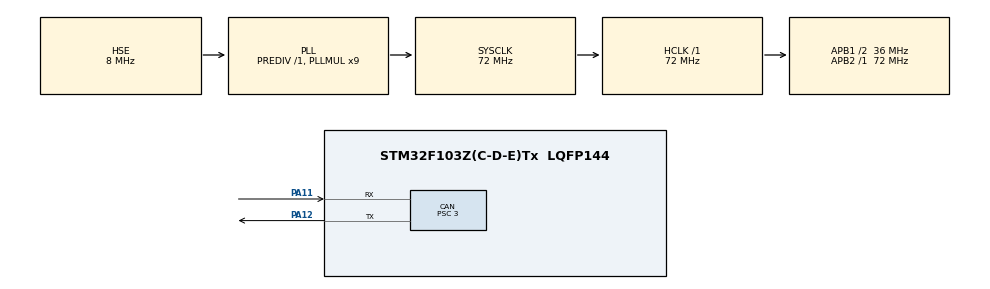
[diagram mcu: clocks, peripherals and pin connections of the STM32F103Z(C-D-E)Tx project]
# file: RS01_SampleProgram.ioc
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CAN.BS1=CAN_BS1_6TQ
CAN.BS2=CAN_BS2_5TQ
CAN.CalculateBaudRate=1000000
CAN.CalculateTimeBit=999.99
CAN.CalculateTimeQuantum=83.33333333333334
CAN.Prescaler=3
Mcu.Family=STM32F1
Mcu.Name=STM32F103Z(C-D-E)Tx
Mcu.Package=LQFP144
NVIC.PriorityGroup=NVIC_PRIORITYGROUP_4
NVIC.USB_LP_CAN1_RX0_IRQn=true\:0\:0\:false\:false\:true\:true\:true
OSC_IN.Mode=HSE-External-Oscillator
OSC_IN.Signal=RCC_OSC_IN
OSC_OUT.Mode=HSE-External-Oscillator
OSC_OUT.Signal=RCC_OSC_OUT
PA11.Mode=CAN_Activate
PA11.Signal=CAN_RX
PA12.Mode=CAN_Activate
PA12.Signal=CAN_TX
PA13.Mode=Serial_Wire
PA13.Signal=SYS_JTMS-SWDIO
PA14.Mode=Serial_Wire
PA14.Signal=SYS_JTCK-SWCLK
ProjectManager.HeapSize=0x200
ProjectManager.StackSize=0x400
ProjectManager.TargetToolchain=MDK-ARM V5.32
RCC.AHBFreq_Value=72000000
RCC.APB1CLKDivider=RCC_HCLK_DIV2
RCC.APB1Freq_Value=36000000
RCC.APB1TimFreq_Value=72000000
RCC.APB2Freq_Value=72000000
RCC.APB2TimFreq_Value=72000000
RCC.HCLKFreq_Value=72000000
RCC.PLLMUL=RCC_PLL_MUL9
RCC.PLLSourceVirtual=RCC_PLLSOURCE_HSE
RCC.SYSCLKFreq_VALUE=72000000
RCC.SYSCLKSource=RCC_SYSCLKSOURCE_PLLCLK
RCC.USBFreq_Value=72000000
board=custom

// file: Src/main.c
/* USER CODE BEGIN Header */
/**
  ******************************************************************************
  * @file           : main.c
  * @brief          : Main program body
  ******************************************************************************
  * @attention
  *
  * <h2><center>&copy; Copyright (c) 2025 STMicroelectronics.
  * All rights reserved.</center></h2>
  *
  * This software component is licensed by ST under BSD 3-Clause license,
  * the "License"; You may not use this file except in compliance with the
  * License. You may obtain a copy of the License at:
  *                        opensource.org/licenses/BSD-3-Clause
  *
  ******************************************************************************
  */
/* USER CODE END Header */
#include "main.h"
#include "can.h"
#include "gpio.h"

/* USER CODE BEGIN Includes */

#include "RobStride.h"
/* USER CODE END Includes */

void SystemClock_Config(void);
/* USER CODE BEGIN PFP */
CAN_FilterTypeDef CAN_FilterStrue;
CAN_TxHeaderTypeDef CAN_TxHeaderStrue;
CAN_RxHeaderTypeDef CAN_RxHeaderStrue;
uint8_t pRxdata[8], pTxdata[8];
RobStride_Motor RobStride_01(0x7F, false);

uint8_t mode = 0;
/* USER CODE END PFP */

int main(void)
{

  /* MCU Configuration--------------------------------------------------------*/

  /* Reset of all peripherals, Initializes the Flash interface and the Systick. */
  HAL_Init();

  /* Configure the system clock */
  SystemClock_Config();

  /* Initialize all configured peripherals */
  MX_GPIO_Init();
  MX_CAN_Init();
  /* USER CODE BEGIN 2 */
  CAN_FilterStrue.FilterBank = 0;
  CAN_FilterStrue.FilterMode = CAN_FILTERMODE_IDMASK;
  CAN_FilterStrue.FilterScale = CAN_FILTERSCALE_16BIT;
  CAN_FilterStrue.FilterIdHigh = 0;
	CAN_FilterStrue.FilterIdLow = 0;
	CAN_FilterStrue.FilterActivation = ENABLE;
	CAN_FilterStrue.FilterFIFOAssignment = CAN_RX_FIFO0;

	HAL_CAN_ConfigFilter(&hcan, &CAN_FilterStrue);
  HAL_CAN_Start(&hcan); //鍚姩CAN
  HAL_CAN_ActivateNotification(&hcan, CAN_IT_RX_FIFO0_MSG_PENDING);

  /* USER CODE END 2 */

  /* Infinite loop */
  /* USER CODE BEGIN WHILE */
  while (1)
  {
    switch(mode)
    {
        // ===== 普通模式接口 =====
        case 0: // 使能（普通模式）
            RobStride_01.Enable_Motor();
            break;
        case 1: // 失能（普通模式）
            RobStride_01.Disenable_Motor(1);
            break;
        case 2: // 运控模式
            HAL_Delay(5);
            RobStride_01.RobStride_Motor_move_control(5, 0, 0, 0.0, 0.0);
            break;
        case 3: // PP位置模式
            RobStride_01.RobStride_Motor_Pos_control(2.0, 2);
						HAL_Delay(5);
            break;
				case 4:	//CSP位置模式
						RobStride_01.RobStride_Motor_CSP_control(2.0, 2.0);
						HAL_Delay(5);
						break;
        case 5: // 速度模式
            RobStride_01.RobStride_Motor_Speed_control(3.5, 5.0);
						HAL_Delay(5);
            break;
        case 6: // 电流模式
            HAL_Delay(5);
            RobStride_01.RobStride_Motor_current_control(1.2);
            break;
        case 7: // 设置机械零点
            RobStride_01.Set_ZeroPos();
            break;
        case 8: // 读取参数
            RobStride_01.Get_RobStride_Motor_parameter(0x7014);
            break;
        case 9: // 设置参数
            RobStride_01.Set_RobStride_Motor_parameter(0x7014, 0.35f, Set_parameter);
            break;
        case 10: // 协议切换（如切MIT协议/Canopen/私有协议）
            RobStride_01.RobStride_Motor_MotorModeSet(0x02); // 0x02=MIT
            break;

        // ===== MIT模式接口（只能用MIT专用函数！） =====
        case 11: // MIT 使能
            RobStride_01.RobStride_Motor_MIT_Enable();
            break;
        case 12: // MIT 失能
            RobStride_01.RobStride_Motor_MIT_Disable();
            break;
        case 13: // MIT 综合控制
						RobStride_01.RobStride_Motor_MIT_SetMotorType(0x01);
            RobStride_01.RobStride_Motor_MIT_Enable();
            HAL_Delay(5);
            RobStride_01.RobStride_Motor_MIT_Control(0, 0, 0, 0, -1.0f);
            break;
        case 14: // MIT 位置控制
						RobStride_01.RobStride_Motor_MIT_SetMotorType(0x01);
						RobStride_01.RobStride_Motor_MIT_Enable();
            HAL_Delay(5);
            RobStride_01.RobStride_Motor_MIT_PositionControl(1.57f, 3.0f);
            break;
        case 15: // MIT 速度控制
						RobStride_01.RobStride_Motor_MIT_SetMotorType(0x02);
						RobStride_01.RobStride_Motor_MIT_Enable();
            HAL_Delay(5);
            RobStride_01.RobStride_Motor_MIT_SpeedControl(4.5f, 3.2f);
            break;
        case 16: // MIT 零点设置（运行前需保证 MIT_Type != positionControl）
            RobStride_01.RobStride_Motor_MIT_SetZeroPos();
            break;
        case 17: // MIT 清错
            RobStride_01.RobStride_Motor_MIT_ClearOrCheckError(0x01);
            break;
        case 18: // MIT 设置电机运行模式
            RobStride_01.RobStride_Motor_MIT_SetMotorType(0x01);
            break;
        case 19: // MIT 设置电机ID
            RobStride_01.RobStride_Motor_MIT_SetMotorId(0x05);
            break;
        case 20: //主动上报
            RobStride_01.RobStride_Motor_ProactiveEscalationSet(0x00);
            break;
        case 21: // 波特率修改
            RobStride_01.RobStride_Motor_BaudRateChange(0x01);
            break;
        case 22: // MIT 参数保存
            RobStride_01.RobStride_Motor_MotorDataSave();
            break;
				case 23: // MIT 协议切换（如切MIT协议/Canopen/私有协议）
						RobStride_01.RobStride_Motor_MIT_MotorModeSet(0x00);
						break;

        default:
            break;
    }
		mode = 24;
		HAL_Delay(50);
    /* USER CODE END WHILE */

  }
}

void SystemClock_Config(void)
{
  RCC_OscInitTypeDef RCC_OscInitStruct = {0};
  RCC_ClkInitTypeDef RCC_ClkInitStruct = {0};

  /** Initializes the RCC Oscillators according to the specified parameters
  * in the RCC_OscInitTypeDef structure.
  */
  RCC_OscInitStruct.OscillatorType = RCC_OSCILLATORTYPE_HSE;
  RCC_OscInitStruct.HSEState = RCC_HSE_ON;
  RCC_OscInitStruct.HSEPredivValue = RCC_HSE_PREDIV_DIV1;
  RCC_OscInitStruct.HSIState = RCC_HSI_ON;
  RCC_OscInitStruct.PLL.PLLState = RCC_PLL_ON;
  RCC_OscInitStruct.PLL.PLLSource = RCC_PLLSOURCE_HSE;
  RCC_OscInitStruct.PLL.PLLMUL = RCC_PLL_MUL9;
  if (HAL_RCC_OscConfig(&RCC_OscInitStruct) != HAL_OK)
  {
    Error_Handler();
  }
  /** Initializes the CPU, AHB and APB buses clocks
  */
  RCC_ClkInitStruct.ClockType = RCC_CLOCKTYPE_HCLK|RCC_CLOCKTYPE_SYSCLK
                              |RCC_CLOCKTYPE_PCLK1|RCC_CLOCKTYPE_PCLK2;
  RCC_ClkInitStruct.SYSCLKSource = RCC_SYSCLKSOURCE_PLLCLK;
  RCC_ClkInitStruct.AHBCLKDivider = RCC_SYSCLK_DIV1;
  RCC_ClkInitStruct.APB1CLKDivider = RCC_HCLK_DIV2;
  RCC_ClkInitStruct.APB2CLKDivider = RCC_HCLK_DIV1;

  if (HAL_RCC_ClockConfig(&RCC_ClkInitStruct, FLASH_LATENCY_2) != HAL_OK)
  {
    Error_Handler();
  }
}

/* USER CODE BEGIN 4 */
CAN_RxHeaderTypeDef RXHeader;
uint8_t RxData[8];
void HAL_CAN_RxFifo0MsgPendingCallback(CAN_HandleTypeDef *hcan)
{

	if(HAL_CAN_GetRxMessage(hcan,CAN_RX_FIFO0,&RXHeader,RxData) == HAL_OK)
	{
		if (RXHeader.IDE == CAN_ID_EXT)
		{
				RobStride_01.RobStride_Motor_Analysis(RxData, RXHeader.ExtId);
		}
		else
		{
				RobStride_01.RobStride_Motor_Analysis(RxData, RXHeader.StdId);
		}
	}
}
/* USER CODE END 4 */

void Error_Handler(void)
{
  __disable_irq();
  while (1)
  {
  }
}

/************************ (C) COPYRIGHT STMicroelectronics *****END OF FILE****/
